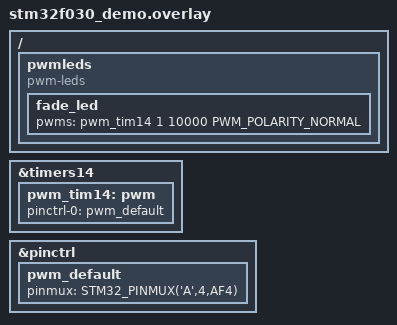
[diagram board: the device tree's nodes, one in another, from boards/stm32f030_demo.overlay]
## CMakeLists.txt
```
cmake_minimum_required(VERSION 3.20.0)

set(BOARD stm32f030_demo)
set(DTO_DIR ${CMAKE_CURRENT_SOURCE_DIR}/boards)
set(DTC_OVERLAY_FILE ${DTO_DIR}/stm32f030_demo.overlay)
find_package(Zephyr REQUIRED HINTS $ENV{ZEPHYR_BASE})

project(led_blink)

target_sources(app PRIVATE src/main.c)
```

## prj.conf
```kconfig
CONFIG_STDOUT_CONSOLE=y
CONFIG_GPIO=y
CONFIG_PWM=y
```

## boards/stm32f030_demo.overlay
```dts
/{
    pwmleds {
        compatible = "pwm-leds";
        fade_led: fade_led {
            pwms = <&pwm_tim14 1 10000 PWM_POLARITY_NORMAL>;
        };
    };

};


&timers14 {
        status = "okay";
        pwm_tim14:pwm{
            status = "okay";
            pinctrl-0=<&pwm_default>;
            pinctrl-names="default";
        };
};


&pinctrl {
    pwm_default: pwm_default{
        pinmux = <STM32_PINMUX('A',4,AF4)>;
    };
};
```

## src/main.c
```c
#include <zephyr/kernel.h>
#include <zephyr/sys/printk.h>
#include <zephyr/drivers/pwm.h>
#include <zephyr/device.h>  

static const struct pwm_dt_spec led = PWM_DT_SPEC_GET(DT_NODELABEL(fade_led));

void main(void){
    if(!device_is_ready(led.dev)){
        printk("Error: PWM device %s is not ready\n",led.dev->name);
        return;
    }
    int ret;
    printk("STARTING LED FADE");
    while(1){
        for(int i = 0;i<10000;i++){
            ret = pwm_set_pulse_dt(&led,i);
            printk("LED STATUS: %d\n",i);
            k_usleep(10);
        }
        k_msleep(300);

        for(int i = 10000;i>0;i--){
            ret = pwm_set_pulse_dt(&led,i);
            printk("LED STATUS: %d\n",i);
            k_usleep(10);
        }
        k_msleep(300);
    }
}
```
